# CANFD0_1.0 register map
Vendor: Texas Instruments
Peripheral module from a debugger description file (folder mspm0g1x0x_g3x0x).
Registers are 32-bit, read-write, no defined reset value unless marked. A register's access mark holds for its fields unless they carry their own. Offsets are as the file gives them; lines under a group give offsets from that group; [hi:lo] are bit positions; {n}, {i} and the like mark numbered series; 'fields as' and 'values as' point back to an identical list; <NAME> marks a mode.

## CANFD0 (part 1 of 3)
0x6800 CANFD0_PWREN — Power enable
  [0] ENABLE — Enable the power
    0=DISABLE (Disable Power); 1=ENABLE (Enable Power)
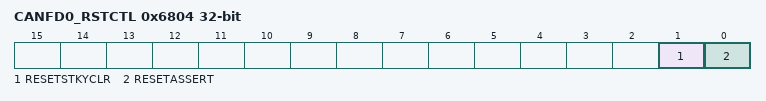
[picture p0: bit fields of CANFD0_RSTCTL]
0x6804 CANFD0_RSTCTL — Reset Control
  [1] RESETSTKYCLR — Clear the RESETSTKY bit in the STAT register
    0=NOP (Writing 0 has no effect); 1=CLR (Clear reset sticky bit)
  [0] RESETASSERT — Assert reset to the peripheral
    0=NOP (Writing 0 has no effect); 1=ASSERT (Assert reset)
0x6814 CANFD0_STAT ro — Status Register
  [16] RESETSTKY — This bit indicates, if the peripheral was reset, since this bit was cleared by RESETSTKYCLR in the RSTCTL register
    0=NORES (The peripheral has not been reset since this bit was last cleared by RESETSTKYCLR in the RSTCTL register); 1=RESET (The peripheral was reset since the last bit clear)
